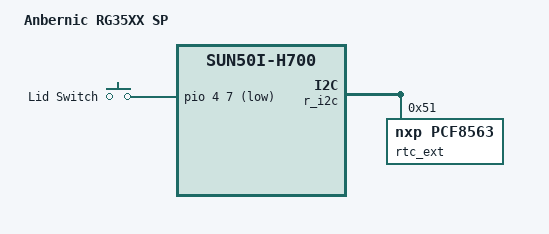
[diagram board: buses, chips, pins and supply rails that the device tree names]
// SPDX-License-Identifier: (GPL-2.0-only OR BSD-2-Clause)
/*
 * Copyright (C) 2024 Ryan Walklin <ryan@testtoast.com>.
 * Copyright (C) 2024 Chris Morgan <macroalpha82@gmail.com>.
 */

#include <dt-bindings/input/gpio-keys.h>
#include "sun50i-h700-anbernic-rg35xx-plus.dts"

/ {
	model = "Anbernic RG35XX SP";
	compatible = "anbernic,rg35xx-sp", "allwinner,sun50i-h700";

	gpio-keys-lid {
		compatible = "gpio-keys";

		lid-switch {
			label = "Lid Switch";
			gpios = <&pio 4 7 GPIO_ACTIVE_LOW>; /* PE7 */
			linux,can-disable;
			linux,code = <SW_LID>;
			linux,input-type = <EV_SW>;
			wakeup-event-action = <EV_ACT_DEASSERTED>;
			wakeup-source;
		};
	};
};

&r_i2c {
	rtc_ext: rtc@51 {
		compatible = "nxp,pcf8563";
		reg = <0x51>;
	};
};
